# RL6678_IP_SVD register map
Vendor: Realtek
Registers are 32-bit, read-write, reset 0x0 unless marked. A register's access mark holds for its fields unless they carry their own. Offsets are from the block's base; [hi:lo] are bit positions; {n}, {i} and the like mark numbered series.

## AUDIO_REG
Base 0x4100B000
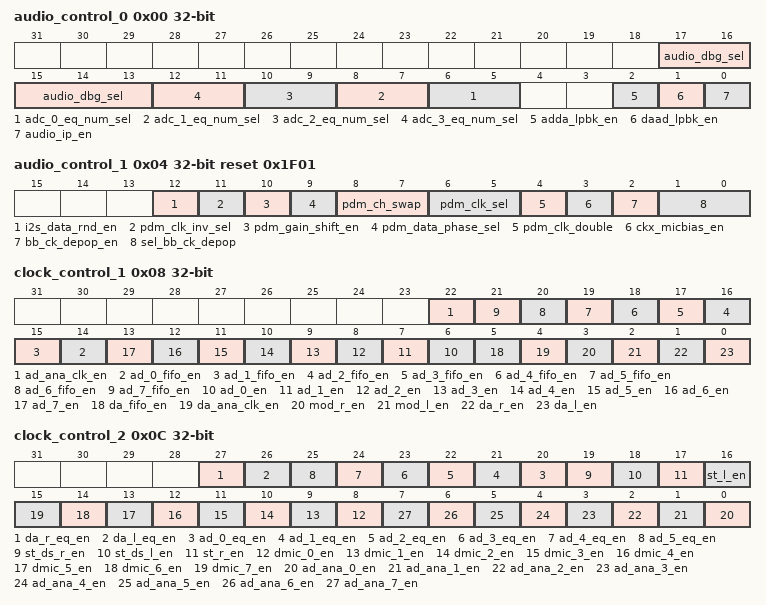
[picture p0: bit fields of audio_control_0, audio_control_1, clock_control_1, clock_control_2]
0x00 audio_control_0 — Audio Control Register 0
  [17:13] audio_dbg_sel — Debug probe selcetion
  [2n+6:2n+5] adc_{n}_eq_num_sel (n=0..3) — 00: 5 band 01: 3 band 02: 0 band 11: Reserved
  [2] adda_lpbk_en — Digital ADC --> DAC loop back control 1'b0: Disable 1'b1: Enable
  [1] daad_lpbk_en — Digital DAC --> ADC loop back control 1'b0: Disable 1'b1: Enable
  [0] audio_ip_en
0x04 audio_control_1 reset 0x1F01 — Audio Control Register 1
  [12] i2s_data_rnd_en
  [11] pdm_clk_inv_sel
  [10] pdm_gain_shift_en
  [9] pdm_data_phase_sel
  [8:7] pdm_ch_swap
  [6:5] pdm_clk_sel — PDM clock selection 2'b0: 5MHz 2'b1: 2.5MHz 2'b2: 6.67MHz
  [4] pdm_clk_double
  [3] ckx_micbias_en
  [2] bb_ck_depop_en
  [1:0] sel_bb_ck_depop
0x08 clock_control_1 — Clock Control Register 1
  [22] ad_ana_clk_en — ADC analog clock enable
  [n+14] ad_{n}_fifo_en (n=0..7) — ADC channel {n} FIFO clock enable
  [n+6] ad_{n}_en (n=0..7) — ADC channel {n} clock enable
  [5] da_fifo_en — DAC FIFO clock enable
  [4] da_ana_clk_en — DAC/ADC analog clock enable
  [3] mod_r_en — SDM R channel clock enable
  [2] mod_l_en — SDM L channel clock enable
  [1] da_r_en — DAC R channel clock enable
  [0] da_l_en — DAC L channel clock enable
0x0C clock_control_2 — Clock Control Register 2
  [27] da_r_eq_en — DAC R channel EQ clock enable
  [26] da_l_eq_en — DAC L channel EQ clock enable
  [n+20] ad_{n}_eq_en (n=0..5) — ADC channel {n} EQ clock enable
  [19] st_ds_r_en — Sidetone downsaple path R channel clock enable
  [18] st_ds_l_en — Sidetone downsaple path L channel clock enable
  [17] st_r_en — Sidetone R channel clock enable
  [16] st_l_en — Sidetone L channel clock enable
  [n+8] dmic_{n}_en (n=0..7) — ADC filter channel {n} clock enable: dmic path
  [n] ad_ana_{n}_en (n=0..7) — ADC filter channel {n} clock enable: analog ADC path
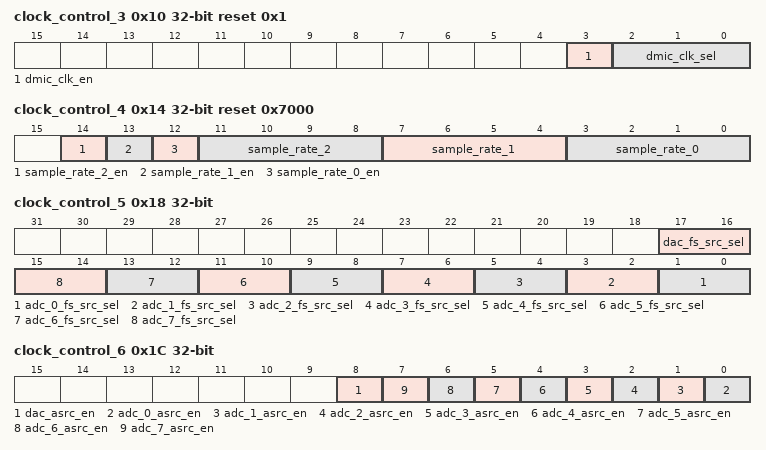
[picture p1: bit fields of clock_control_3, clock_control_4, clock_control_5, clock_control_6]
0x10 clock_control_3 reset 0x1 — Clock Control Register 3
  [3] dmic_clk_en — Digital microphone clock enable
  [2:0] dmic_clk_sel — Set clock of digital microphone 3'b000: 5MHz 3'b001: 2.5MHz 3'b010: 1.25MHz 3'b011: 625kHz 3'b100: 312.5kHz 3'b101: Reserved 3'b110: Reserved 3'b111: 769.2kHz
0x14 clock_control_4 reset 0x7000 — Clock Control Register 4
  [14] sample_rate_2_en — Sample rate source 2 power enable
  [13] sample_rate_1_en — Sample rate source 1 power enable
  [12] sample_rate_0_en — Sample rate source 0 power enable
  [11:8] sample_rate_2 — Set sample rate source 2 4'h0: 48K 4'h1: 96K 4'h2: 192K 4'h3: 32K 4'h4: 176.4K 4'h5: 16K 4'h6: Reserved 4'h7: 8K 4'h8: 44.1K 4'h9: 88.2K 4'ha:24K 4'hb: 12K 4'hc: 22.05K 4'hd: 11.025K 4'he~4'hf: Reserved
  [7:4] sample_rate_1 — Set sample rate source 1 4'h0: 48K 4'h1: 96K 4'h2: 192K 4'h3: 32K 4'h4: 176.4K 4'h5: 16K 4'h6: Reserved 4'h7: 8K 4'h8: 44.1K 4'h9: 88.2K 4'ha:24K 4'hb: 12K 4'hc: 22.05K 4'hd: 11.025K 4'he~4'hf: Reserved
  [3:0] sample_rate_0 — Set sample rate source 0 4'h0: 48K 4'h1: 96K 4'h2: 192K 4'h3: 32K 4'h4: 176.4K 4'h5: 16K 4'h6: Reserved 4'h7: 8K 4'h8: 44.1K 4'h9: 88.2K 4'ha:24K 4'hb: 12K 4'hc: 22.05K 4'hd: 11.025K 4'he~4'hf: Reserved
0x18 clock_control_5 — Clock Control Register 5
  [17:16] dac_fs_src_sel — DAC path sample rate source selection 2'b00: Source 0 2'b01: Source 1 2'b10: Source 2
  [2n+1:2n] adc_{n}_fs_src_sel (n=0..7) — Channel {n} ADC path sample rate source selection 2'b00: Source 0 2'b01: Source 1 2'b10: Source 2
0x1C clock_control_6 — Clock Control Register 6
  [8] dac_asrc_en — DAC path ASRC enable 0: Disable 1: Enable If ASRC is enabled, sample_rate becomes useless.
  [n] adc_{n}_asrc_en (n=0..7) — Channel {n} ADC path ASRC enable 0: Disable 1: Enable If ASRC is enabled, sample_rate becomes useless.
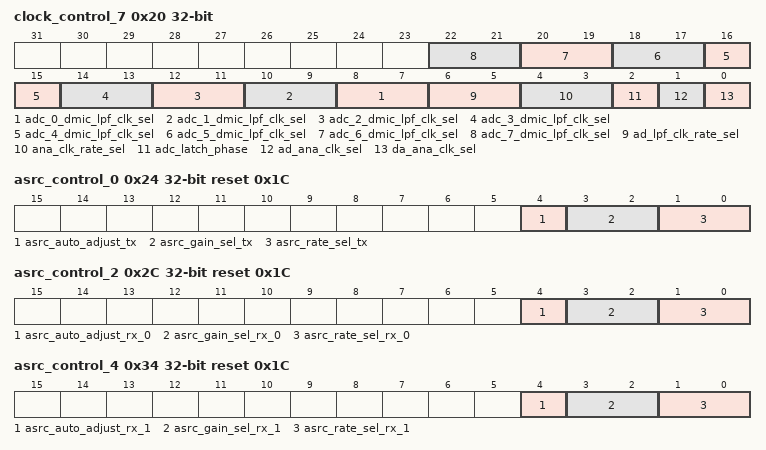
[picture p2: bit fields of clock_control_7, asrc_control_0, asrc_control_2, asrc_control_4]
0x20 clock_control_7 — Clock Control Register 7
  [2n+8:2n+7] adc_{n}_dmic_lpf_clk_sel (n=0..7) — Channel {n} ADC path DMIC LPF clock 2'b00: 10M 2'b01: 5M 2'b10: 2.5M 2'b11: 769.2*2K
  [6:5] ad_lpf_clk_rate_sel — Set AD LPF clock 0: 10MHz 1: 5MHz 2: 2.5MHz 3: Reserved
  [4:3] ana_clk_rate_sel — Set DA/AD analog clock 0: 10MHz 1: 5MHz 2: 2.5MHz 3: Reserved
  [2] adc_latch_phase — Set latch adc data phase 1'b0: Inphase 1'b1: Inverse phase
  [1] ad_ana_clk_sel — Set clk_ad_ana phase 1'b0: Inphase 1'b1: Inverse phase
  [0] da_ana_clk_sel — Set clk_da_ana phase 1'b0: Inphase 1'b1: Inverse phase
0x24 asrc_control_0 reset 0x1C
  [4] asrc_auto_adjust_tx — HW auto adjust convergence rate 0: Disable 1: Enable
  [3:2] asrc_gain_sel_tx — ASRC convergence rate: larger is faster but more noisy
  [1:0] asrc_rate_sel_tx — 0: fs supports 4kHz ~ 60kHz 1: fs supports 60kHz ~ 120kHz 2: fs supports 120kHz ~ 200kHz 3: Reserved
0x28 asrc_control_1 — ASRC Control Register 1
  [23:0] asrc_sdm_inti_tx — Set initial value of tracked frequency
0x2C asrc_control_2 reset 0x1C — ASRC Control Register 2
  [4] asrc_auto_adjust_rx_0 — HW auto adjust convergence rate 0: Disable 1: Enable
  [3:2] asrc_gain_sel_rx_0 — ASRC convergence rate: larger is faster but more noisy
  [1:0] asrc_rate_sel_rx_0 — 0: fs supports 4kHz ~ 60kHz 1: fs supports 60kHz ~ 120kHz 2/3: Reserved
0x30 asrc_control_3 — ASRC Control Register 3
  [23:0] asrc_sdm_inti_rx_0 — Set initial value of tracked frequency
0x34 asrc_control_4 reset 0x1C — ASRC Control Register 4
  [4] asrc_auto_adjust_rx_1 — HW auto adjust convergence rate 0: Disable 1: Enable
  [3:2] asrc_gain_sel_rx_1 — ASRC convergence rate: larger is faster but more noisy
  [1:0] asrc_rate_sel_rx_1 — 0: fs supports 4kHz ~ 60kHz 1: fs supports 60kHz ~ 120kHz 2/3: Reserved
0x38 asrc_control_5 — ASRC Control Register 5
  [23:0] asrc_sdm_inti_rx_1 — Set initial value of tracked frequency
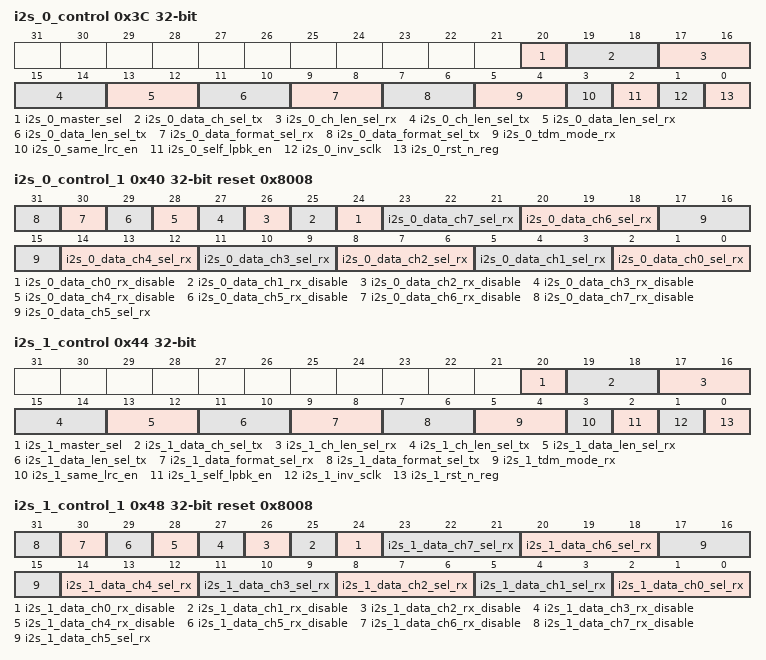
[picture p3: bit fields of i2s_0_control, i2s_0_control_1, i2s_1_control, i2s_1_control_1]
0x3C i2s_0_control
  [20] i2s_0_master_sel — I2S 0 master source selection 1'b0: SPORT internal 1'b1: external I2S
  [19:18] i2s_0_data_ch_sel_tx — I2S 0 Tx channel data channel 2'b00: L/R 2'b01: R/L 2'b10: L/L 2'b11: R/R
  [17:16] i2s_0_ch_len_sel_rx — I2S 0 Rx channel chennel length 2'b00: 16 bits 2'b01: 32 bits 2'b10: 24 bits 2'b11: 8 bits
  [15:14] i2s_0_ch_len_sel_tx — I2S 0 Tx channel channel length 2'b00: 16 bits 2'b01: 32 bits 2'b10: 24 bits 2'b11: 8 bits
  [13:12] i2s_0_data_len_sel_rx — I2S 0 Rx channel data length 2'b00: 16 bits 2'b10: 24 bits 2'b11: 8 bits
  [11:10] i2s_0_data_len_sel_tx — I2S 0 Tx channel data length 2'b00: 16 bits 2'b10: 24 bits 2'b11: 8 bits
  [9:8] i2s_0_data_format_sel_rx — I2S 0 Rx channel data format 2'b00: I2S 2'b01: left-justified 2'b10: PCM mode A 2'b11: PCM mode B
  [7:6] i2s_0_data_format_sel_tx — I2S 0 Tx channel data format 2'b00: I2S 2'b01: left-justified 2'b10: PCM mode A 2'b11: PCM mode B
  [5:4] i2s_0_tdm_mode_rx — I2S 0 Rx channel TDM mode 0: 2 channels 1: 4 channels 2: 6 channels 3: 8 channels
  [3] i2s_0_same_lrc_en — I2S 0 1'b1: LRC_TX share to LRC_RX
  [2] i2s_0_self_lpbk_en — I2S 0 1'b1: internal loopback mode is enabled
  [1] i2s_0_inv_sclk — I2S 0 1'b1: I2S/PCM bit clock is inverted
  [0] i2s_0_rst_n_reg — I2S 0 1'b1: rst_n to audio digital IP is de-asserted 1'b0: rst_n to audio digital IP is asserted
0x40 i2s_0_control_1 reset 0x8008 — I2S 0 Control Register 1
  [n+24] i2s_0_data_ch{n}_rx_disable (n=0..7) — I2S 0 Rx channel data channel {n} 1: Disable 0: Enable
  [3n+2:3n] i2s_0_data_ch{n}_sel_rx (n=0..7) — I2S 0 Rx channel data channel {n} 0: CH0 1: CH1 2: CH2 3: CH3 4: CH4 5: CH5 6: CH6 7: CH7
0x44 i2s_1_control
  [20] i2s_1_master_sel — I2S 1 master source selection 1'b0: SPORT internal 1'b1: external I2S
  [19:18] i2s_1_data_ch_sel_tx — I2S 1 Tx channel data channel 2'b00: L/R 2'b01: R/L 2'b10: L/L 2'b11: R/R
  [17:16] i2s_1_ch_len_sel_rx — I2S 1 Rx channel chennel length 2'b00: 16 bits 2'b01: 32 bits 2'b10: 24 bits 2'b11: 8 bits
  [15:14] i2s_1_ch_len_sel_tx — I2S 1 Tx channel channel length 2'b00: 16 bits 2'b01: 32 bits 2'b10: 24 bits 2'b11: 8 bits
  [13:12] i2s_1_data_len_sel_rx — I2S 1 Rx channel data length 2'b00: 16 bits 2'b10: 24 bits 2'b11: 8 bits
  [11:10] i2s_1_data_len_sel_tx — I2S 1 Tx channel data length 2'b00: 16 bits 2'b10: 24 bits 2'b11: 8 bits
  [9:8] i2s_1_data_format_sel_rx — I2S 1 Rx channel data format 2'b00: I2S 2'b01: left-justified 2'b10: PCM mode A 2'b11: PCM mode B
  [7:6] i2s_1_data_format_sel_tx — I2S 1 Tx channel data format 2'b00: I2S 2'b01: left-justified 2'b10: PCM mode A 2'b11: PCM mode B
  [5:4] i2s_1_tdm_mode_rx — I2S 1 Rx channel TDM mode 0: 2 channels 1: 4 channels 2: 6 channels 3: 8 channels
  [3] i2s_1_same_lrc_en — I2S 1 1'b1: LRC_TX share to LRC_RX
  [2] i2s_1_self_lpbk_en — I2S 1 1'b1: internal loopback mode is enabled
  [1] i2s_1_inv_sclk — I2S 1 1'b1: I2S/PCM bit clock is inverted
  [0] i2s_1_rst_n_reg — I2S 1 1'b1: rst_n to audio digital IP is de-asserted 1'b0: rst_n to audio digital IP is asserted
0x48 i2s_1_control_1 reset 0x8008 — I2S 1 Control Register 1
  [n+24] i2s_1_data_ch{n}_rx_disable (n=0..7) — I2S 1 Rx channel data channel {n} 1: Disable 0: Enable
  [3n+2:3n] i2s_1_data_ch{n}_sel_rx (n=0..7) — I2S 1 Rx channel data channel {n} 0: CH0 1: CH1 2: CH2 3: CH3 4: CH4 5: CH5 6: CH6 7: CH7
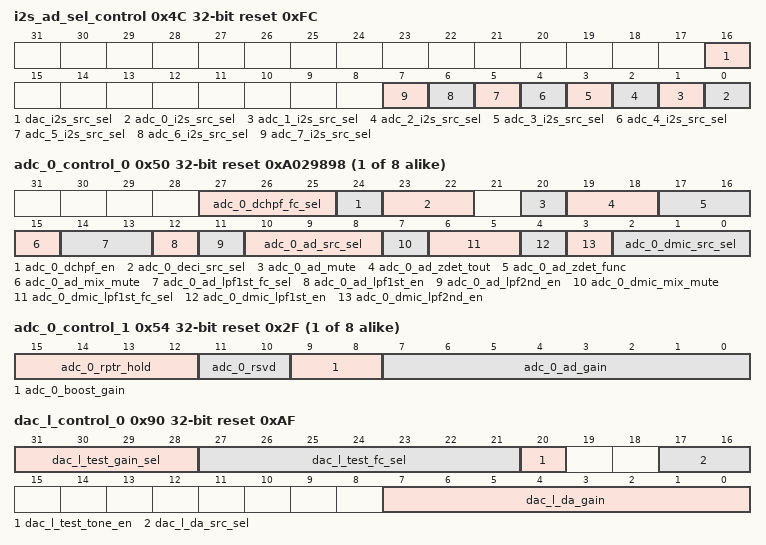
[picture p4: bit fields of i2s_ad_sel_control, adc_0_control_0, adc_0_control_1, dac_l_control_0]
0x4C i2s_ad_sel_control reset 0xFC — I2S ADC Selection Control Register
  [16] dac_i2s_src_sel — DAC path I2S selection 1: I2S 1 0: I2S 0
  [n] adc_{n}_i2s_src_sel (n=0..7) — Channel {n} ADC path I2S selection 1: I2S 1 0: I2S 0
{0x50+8i} adc_{i}_control_0 reset 0xA029898 (i=0..7) — ADC Channel {i} Control Register 0
  [27:25] adc_{i}_dchpf_fc_sel — Channel {i} ADC path high pass filter Fc (Fc: -3dB) 0: 5e10^-3 Fs 1: 2.5e10^-3 Fs 2: 1.125e10^-3 Fs 3: 6.25e10^-4 Fs 4: 3.125e10^-4 Fs 5: 1.5625e10^-4 Fs 6: 7.8125e10^-5 Fs 7: 3.90625e10^-5 Fs
  [24] adc_{i}_dchpf_en — Channel {i} ADC path high pass filter enable control (filter DC) 0: Disable 1: Enable
  [23:22] adc_{i}_deci_src_sel — Channel {i} ADC path decimation source select 0: ADC 1: ANC 2: MUSIC 3: ANC + MUSIC
  [20] adc_{i}_ad_mute — Channel {i} ADC path mute 0: Un-Mute 1: Mute
  [19:18] adc_{i}_ad_zdet_tout — Channel {i} ADC path zero detection time out select 2'b00: 1024*16 samples 2'b01: 1024*32 samples 2'b10: 1024*64 samples 2'b11: 64 samples
  [17:16] adc_{i}_ad_zdet_func — Channel {i} ADC path zero detection function select 2'b00: immediate change 2'b01: zero detection & immediate change 2'b10: zdet & step 2'b11: zdet & timeout step
  [15] adc_{i}_ad_mix_mute — Channel {i} ADC input path mute 0: Unmute 1: Mute
  [14:13] adc_{i}_ad_lpf1st_fc_sel — Channel {i} ADC path SRC 1st LPF FC
  [12] adc_{i}_ad_lpf1st_en — Channel {i} ADC path SRC 1st LPF control 0: Disable 1: Enable
  [11] adc_{i}_ad_lpf2nd_en — Channel {i} ADC path SRC 2nd LPF control 0: Disable 1: Enable
  [10:8] adc_{i}_ad_src_sel — Channel {i} ANA ADC source selection 3'd0: ADC 1 3'd1: ADC 2 3'd2: ADC 3 3'd3: ADC 4 3'd4: ADC 5
  [7] adc_{i}_dmic_mix_mute — Channel {i} DMIC input path mute 0: Unmute 1: Mute
  [6:5] adc_{i}_dmic_lpf1st_fc_sel — Channel {i} DMIC path SRC 1st LPF FC
  [4] adc_{i}_dmic_lpf1st_en — Channel {i} DMIC path SRC 1st LPF control 0: Disable 1: Enable
  [3] adc_{i}_dmic_lpf2nd_en — Channel {i} DMIC path SRC 2nd LPF control 0: Disable 1: Enable
  [2:0] adc_{i}_dmic_src_sel — Channel {i} DMIC source selection 3'b000: MIC 1 rising 3'b001: MIC 1 falling 3'b010: MIC 2 rising 3'b011: MIC 2 falling 3'b100: MIC 3 rising 3'b101: MIC 3 falling 3'b110: MIC 4 rising 3'b111: MIC 4 falling
{0x54+8i} adc_{i}_control_1 reset 0x2F (i=0..7) — ADC Channel {i} Control Register 1
  [15:12] adc_{i}_rptr_hold — Channel {i} I2S read point hold number rptr_hold = (I2S_fs/ad_fs) - 1
  [11:10] adc_{i}_rsvd — Dummy
  [9:8] adc_{i}_boost_gain — Channel {i} ADC path boost gain control 00: 0dB 01: 12dB 10: 24dB 11: 36dB
  [7:0] adc_{i}_ad_gain — Channel {i} ADC digital volume -17.625dB ~ 48dB in 0.375dB step 8'h00: -17.625dB ... 8'h2f: 0dB 8'h30: 0.375dB ... 8'haf: 48dB
0x90 dac_l_control_0 reset 0xAF — DAC Left Channel Control Register 0
  [31:28] dac_l_test_gain_sel — Channel L DAC path test tone gain control 0 -6.02*(gain_sel)dB
  [27:21] dac_l_test_fc_sel — Channel L DAC path test tone frquency: (fs/192)*(tone_fc_sel+1)Hz
  [20] dac_l_test_tone_en — Channel L DAC path test tone enable
  [17:16] dac_l_da_src_sel — Channel L DAC path input select 0: I2S L channel 1: I2S R channel 2: I2S L+R channel 3: Test tone
  [7:0] dac_l_da_gain — Channel L DAC path dvol gain control (0.375dB/step) 8'hAF: 0dB 8'h00: -65.625dB
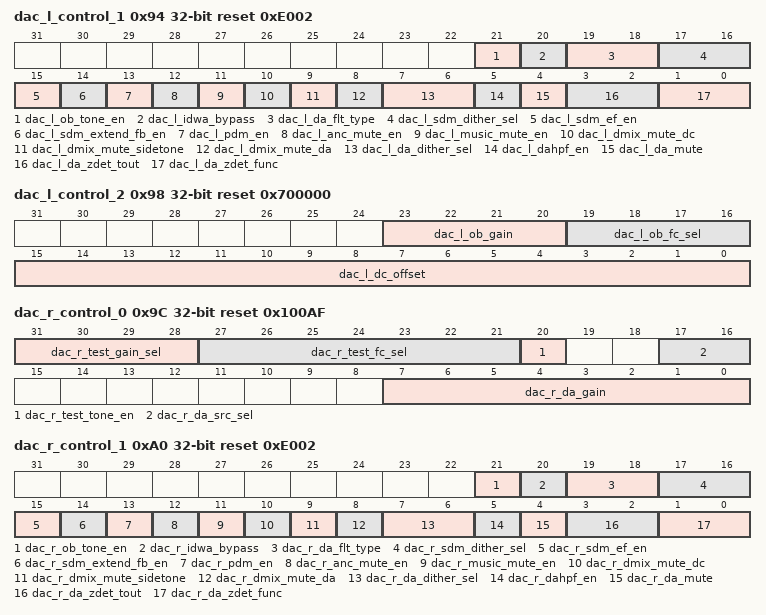
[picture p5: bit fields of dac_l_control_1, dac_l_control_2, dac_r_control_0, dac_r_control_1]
0x94 dac_l_control_1 reset 0xE002 — DAC Left Channel Control Register 1
  [21] dac_l_ob_tone_en — Channel L DAC path Out Band tone enable 0: Disable 1: Enable
  [20] dac_l_idwa_bypass — Channel L DAC path IDWA BYPASS mode 0: Disable 1: Enable (debug purpose)
  [19:18] dac_l_da_flt_type — Channel L DAC path interpolation filter type
  [17:16] dac_l_sdm_dither_sel — Channel L DAC path SDM dither select 2'b00: Disable 2'b01: LSB 2'b10: LSB+1 2'b11: LSB+2
  [15] dac_l_sdm_ef_en — Channel L DAC path 2nd order SDM enable 0: Disable 1: Enable
  [14] dac_l_sdm_extend_fb_en — Channel L DAC path feedback extend (for debug purpose; default need turn on) 0: Disable 1: Enable
  [13] dac_l_pdm_en — Channel L DAC path PDM 0: Disable 1: Enable
  [12] dac_l_anc_mute_en — Channel L DAC path ANC output mute enable 1'b0: Unmute 1'b1: Mute
  [11] dac_l_music_mute_en — Channel L DAC path music output mute enable 1'b0: Unmute 1'b1: Mute
  [10] dac_l_dmix_mute_dc — Channel L DAC path 128fs-domain mixer a DC from dac_l_tone_compensation_offset 1'b0: Unmute 1'b1: Mute
  [9] dac_l_dmix_mute_sidetone — Channel L DAC path 128fs-domain mixer sidetone path mute enable 1'b0: Unmute 1'b1: Mute
  [8] dac_l_dmix_mute_da — Channel L DAC path 128fs-domain mixer da path mute enable 1'b0: Unmute 1'b1: Mute
  [7:6] dac_l_da_dither_sel — Channel L DAC path dither select 2'b00: Disable 2'b01: LSB 2'b10: LSB+1 2'b11: LSB+2
  [5] dac_l_dahpf_en — Channel L DAC path Narrow-band 1st HPF enable control 0: Disable 1: Enable
  [4] dac_l_da_mute — Channel L DAC path dvol mute enable 1'b0: Unmute 1'b1: Mute
  [3:2] dac_l_da_zdet_tout — Channel L DAC path zero detection time out select 2'b00: 1024*16 samples 2'b01: 1024*32 samples 2'b10: 1024*64 samples 2'b11: 64 samples
  [1:0] dac_l_da_zdet_func — Channel L DAC path zero detection function select 2'b00: immediate change 2'b01: zero detection & immediate change 2'b10: zero detection & step 2'b11: zero detection & timeout step
0x98 dac_l_control_2 reset 0x700000 — DAC Left Channel Control Register 2
  [23:20] dac_l_ob_gain — Channel L DAC path out Band tone gain -20dB - (6 * dac_l_ob_gain )
  [19:16] dac_l_ob_fc_sel — Channel L DAC path out Band tone frequency 100kHz * (dac_l_ob_fc_sel+1)
  [15:0] dac_l_dc_offset — Channel L DAC path 128fs-domain mixe a DC compensation for spur issue 2's complemet
0x9C dac_r_control_0 reset 0x100AF — DAC Right Channel Control Register 0
  [31:28] dac_r_test_gain_sel — Channel R DAC path test tone gain control 0 -6.02*(gain_sel)dB
  [27:21] dac_r_test_fc_sel — Channel R DAC path test tone frquency: (fs/192)*(tone_fc_sel+1)Hz
  [20] dac_r_test_tone_en — Channel R DAC path test tone enable
  [17:16] dac_r_da_src_sel — Channel R DAC path input select 0: I2S L channel 1: I2S R channel 2: I2S L+R channel 3: Test tone
  [7:0] dac_r_da_gain — Channel R DAC path dvol gain control (0.375dB/step) 8'hAF: 0dB 8'h00: -65.625dB
0xA0 dac_r_control_1 reset 0xE002 — DAC Right Channel Control Register 1
  [21] dac_r_ob_tone_en — Channel R DAC path Out Band tone enable 0: Disable 1: Enable
  [20] dac_r_idwa_bypass — Channel R DAC path IDWA BYPASS mode 0: Disable 1: Enable (debug purpose)
  [19:18] dac_r_da_flt_type — Channel R DAC path interpolation filter type
  [17:16] dac_r_sdm_dither_sel — Channel R DAC path SDM dither select 2'b00: Disable 2'b01: LSB 2'b10: LSB+1 2'b11: LSB+2
  [15] dac_r_sdm_ef_en — Channel R DAC path 2nd order SDM enable 0: Disable 1: Enable
  [14] dac_r_sdm_extend_fb_en — Channel R DAC path feedback extend (for debug purpose; default need turn on) 0: Disable 1: Enable
  [13] dac_r_pdm_en — Channel R DAC path PDM 0: Disable 1: Enable
  [12] dac_r_anc_mute_en — Channel R DAC path ANC output mute enable 1'b0: Unmute 1'b1: Mute
  [11] dac_r_music_mute_en — Channel R DAC path music output mute enable 1'b0: Unmute 1'b1: Mute
  [10] dac_r_dmix_mute_dc — Channel R DAC path 128fs-domain mixer a DC from dac_r_tone_compensation_offset 1'b0: Unmute 1'b1: Mute
  [9] dac_r_dmix_mute_sidetone — Channel R DAC path 128fs-domain mixer sidetone path mute enable 1'b0: Unmute 1'b1: Mute
  [8] dac_r_dmix_mute_da — Channel R DAC path 128fs-domain mixer da path mute enable 1'b0: Unmute 1'b1: Mute
  [7:6] dac_r_da_dither_sel — Channel R DAC path dither select 2'b00: Disable 2'b01: LSB 2'b10: LSB+1 2'b11: LSB+2
  [5] dac_r_dahpf_en — Channel R DAC path Narrow-band 1st HPF enable control 0: Disable 1: Enable
  [4] dac_r_da_mute — Channel R DAC path dvol mute enable 1'b0: Unmute 1'b1: Mute
  [3:2] dac_r_da_zdet_tout — Channel R DAC path zero detection time out select 2'b00: 1024*16 samples 2'b01: 1024*32 samples 2'b10: 1024*64 samples 2'b11: 64 samples
  [1:0] dac_r_da_zdet_func — Channel R DAC path zero detection function select 2'b00: immediate change 2'b01: zero detection & immediate change 2'b10: zero detection & step 2'b11: zero detection & timeout step
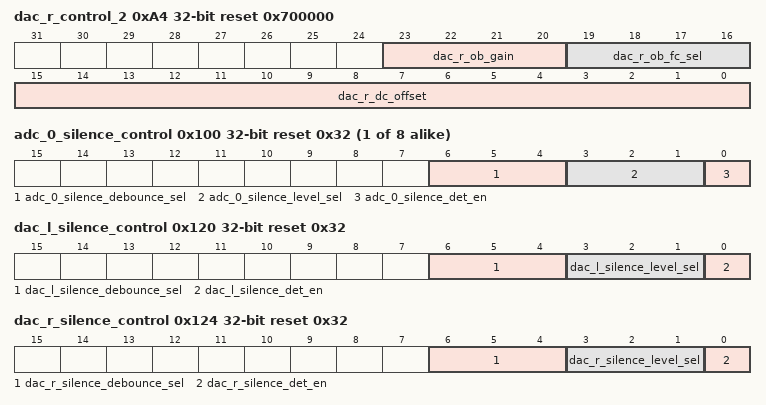
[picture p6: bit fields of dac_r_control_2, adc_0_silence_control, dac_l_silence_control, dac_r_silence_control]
0xA4 dac_r_control_2 reset 0x700000 — DAC Right Channel Control Register 2
  [23:20] dac_r_ob_gain — Channel R DAC path out Band tone gain -20dB - (6 * dac_l_ob_gain )
  [19:16] dac_r_ob_fc_sel — Channel R DAC path out Band tone frequency 100kHz * (dac_l_ob_fc_sel+1)
  [15:0] dac_r_dc_offset — Channel R DAC path 128fs-domain mixe a DC compensation for spur issue 2's complemet
{0x100+4i} adc_{i}_silence_control reset 0x32 (i=0..7) — ADC Channel {i} Silence Control Register
  [6:4] adc_{i}_silence_debounce_sel — Channel {i} ADC path silence detection debounce (48K) 3'b000: 80ms 3'b001: 160ms 3'b010: 320ms 3'b011: 640ms 3'b100: 1.28s 3'b101: 2.56s 3'b110: 5.12s 3'b111: 0.16ms
  [3:1] adc_{i}_silence_level_sel — Channel {i} ADC path silence detection threshold 3'b000: -54db 3'b001: -60db 3'b010: -66db 3'b011: -72db 3'b100: -78db 3'b101: -84db 3'b110: -90db 3'b111: -96db
  [0] adc_{i}_silence_det_en — Channel {i} ADC path silence detection enable 0: Disable 1: Enable
0x120 dac_l_silence_control reset 0x32 — DAC Left Channel Silence Control Register
  [6:4] dac_l_silence_debounce_sel — Channel L DAC path silence detection debounce (48K) 3'b000: 80ms 3'b001: 160ms 3'b010: 320ms 3'b011: 640ms 3'b100: 1.28s 3'b101: 2.56s 3'b110: 5.12s 3'b111: 0.16ms
  [3:1] dac_l_silence_level_sel — Channel L DAC path silence detection threshold 3'b000: -78db 3'b001: -84db 3'b010: -90db 3'b011: -102db 3'b100: -108db 3'b101: -114db 3'b110: -126db 3'b111: -132db
  [0] dac_l_silence_det_en — Channel L DAC path silence detection enable 0: Disable 1: Enable
0x124 dac_r_silence_control reset 0x32 — DAC Right Channel Silence Control Register
  [6:4] dac_r_silence_debounce_sel — Channel R DAC path silence detection debounce (48K) 3'b000: 80ms 3'b001: 160ms 3'b010: 320ms 3'b011: 640ms 3'b100: 1.28s 3'b101: 2.56s 3'b110: 5.12s 3'b111: 0.16ms
  [3:1] dac_r_silence_level_sel — Channel R DAC path silence detection threshold 3'b000: -78db 3'b001: -84db 3'b010: -90db 3'b011: -102db 3'b100: -108db 3'b101: -114db 3'b110: -126db 3'b111: -132db
  [0] dac_r_silence_det_en — Channel R DAC path silence detection enable 0: Disable 1: Enable
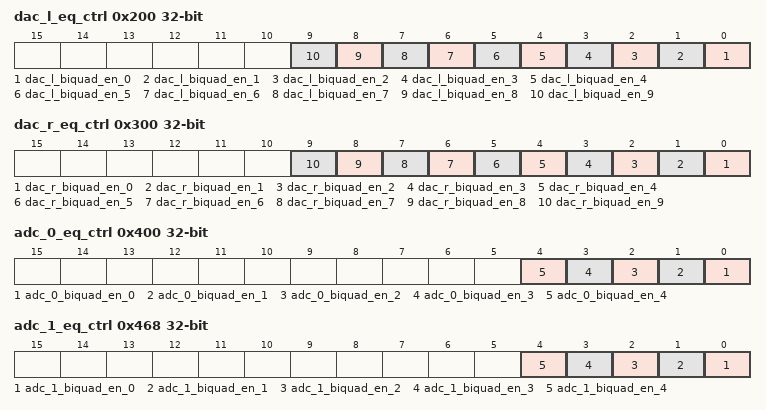
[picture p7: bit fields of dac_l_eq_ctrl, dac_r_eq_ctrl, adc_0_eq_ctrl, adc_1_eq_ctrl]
0x200 dac_l_eq_ctrl — DAC Left Channel EQ Control Register
  [n] dac_l_biquad_en_{n} (n=0..9) — DAC Lch EQ {n}-band biquad enable 0: Disable 1: Enable
{0x204+0x14*i} dac_l_biquad_h0_{i} reset 0x2000000 (i=0..9) — DAC Left Channel EQ Band {i} Biquad H0 Register
  [28:0] dac_l_biquad_h0_{i} — DAC Lch EQ {i}-band coef. h0 2's complement in 4.25 format, i. e. the range is from -8~7.99.
{0x208+0x14*i} dac_l_biquad_b1_{i} (i=0..9) — DAC Left Channel EQ Band {i} Biquad B1 Register
  [28:0] dac_l_biquad_b1_{i} — DAC Lch EQ {i}-band coef. b1 2's complement in 4.25 format, i. e. the range is from -8~7.99.
{0x20C+0x14*i} dac_l_biquad_b2_{i} (i=0..9) — DAC Left Channel EQ Band {i} Biquad B2 Register
  [28:0] dac_l_biquad_b2_{i} — DAC Lch EQ {i}-band coef. b2 2's complement in 4.25 format, i. e. the range is from -8~7.99.
{0x210+0x14*i} dac_l_biquad_a1_{i} (i=0..9) — DAC Left Channel EQ Band {i} Biquad A1 Register
  [28:0] dac_l_biquad_a1_{i} — DAC Lch EQ {i}-band coef. a1 2's complement in 4.25 format, i. e. the range is from -8~7.99.
{0x214+0x14*i} dac_l_biquad_a2_{i} (i=0..9) — DAC Left Channel EQ Band {i} Biquad A2 Register
  [28:0] dac_l_biquad_a2_{i} — DAC Lch EQ {i}-band coef. a2 2's complement in 4.25 format, i. e. the range is from -8~7.99.
0x300 dac_r_eq_ctrl — DAC Right Channel EQ Control Register
  [n] dac_r_biquad_en_{n} (n=0..9) — DAC Rch EQ {n}-band biquad enable 0: Disable 1: Enable
{0x304+0x14*i} dac_r_biquad_h0_{i} reset 0x2000000 (i=0..9) — DAC Right Channel EQ Band {i} Biquad H0 Register
  [28:0] dac_r_biquad_h0_{i} — DAC Rch EQ {i}-band coef. h0 2's complement in 4.25 format, i. e. the range is from -8~7.99.
{0x308+0x14*i} dac_r_biquad_b1_{i} (i=0..9) — DAC Right Channel EQ Band {i} Biquad B1 Register
  [28:0] dac_r_biquad_b1_{i} — DAC Rch EQ {i}-band coef. b1 2's complement in 4.25 format, i. e. the range is from -8~7.99.
{0x30C+0x14*i} dac_r_biquad_b2_{i} (i=0..9) — DAC Right Channel EQ Band {i} Biquad B2 Register
  [28:0] dac_r_biquad_b2_{i} — DAC Rch EQ {i}-band coef. b2 2's complement in 4.25 format, i. e. the range is from -8~7.99.
{0x310+0x14*i} dac_r_biquad_a1_{i} (i=0..9) — DAC Right Channel EQ Band {i} Biquad A1 Register
  [28:0] dac_r_biquad_a1_{i} — DAC Rch EQ {i}-band coef. a1 2's complement in 4.25 format, i. e. the range is from -8~7.99.
{0x314+0x14*i} dac_r_biquad_a2_{i} (i=0..9) — DAC Right Channel EQ Band {i} Biquad A2 Register
  [28:0] dac_r_biquad_a2_{i} — DAC Rch EQ {i}-band coef. a2 2's complement in 4.25 format, i. e. the range is from -8~7.99.
0x400 adc_0_eq_ctrl — ADC Channel 0 EQ Control Register
  [n] adc_0_biquad_en_{n} (n=0..4) — ADC channel 0 EQ {n}-band biquad enable 0: Disable 1: Enable
{0x404+0x14*i} adc_0_biquad_h0_{i} reset 0x2000000 (i=0..4) — ADC Channel 0 EQ Band {i} Biquad H0 Register
  [28:0] adc_0_biquad_h0_{i} — ADC channel 0 EQ {i}-band coef. h0 2's complement in 4.25 format, i. e. the range is from -8~7.99.
{0x408+0x14*i} adc_0_biquad_b1_{i} (i=0..4) — ADC Channel 0 EQ Band {i} Biquad B1 Register
  [28:0] adc_0_biquad_b1_{i} — ADC channel 0 EQ {i}-band coef. b1 2's complement in 4.25 format, i. e. the range is from -8~7.99.
{0x40C+0x14*i} adc_0_biquad_b2_{i} (i=0..4) — ADC Channel 0 EQ Band {i} Biquad B2 Register
  [28:0] adc_0_biquad_b2_{i} — ADC channel 0 EQ {i}-band coef. b2 2's complement in 4.25 format, i. e. the range is from -8~7.99.
{0x410+0x14*i} adc_0_biquad_a1_{i} (i=0..4) — ADC Channel 0 EQ Band {i} Biquad A1 Register
  [28:0] adc_0_biquad_a1_{i} — ADC channel 0 EQ {i}-band coef. a1 2's complement in 4.25 format, i. e. the range is from -8~7.99.
{0x414+0x14*i} adc_0_biquad_a2_{i} (i=0..4) — ADC Channel 0 EQ Band {i} Biquad A2 Register
  [28:0] adc_0_biquad_a2_{i} — ADC channel 0 EQ {i}-band coef. a2 2's complement in 4.25 format, i. e. the range is from -8~7.99.
0x468 adc_1_eq_ctrl — ADC Channel 1 EQ Control Register
  [n] adc_1_biquad_en_{n} (n=0..4) — ADC channel 1 EQ {n}-band biquad enable 0: Disable 1: Enable
{0x46C+0x14*i} adc_1_biquad_h0_{i} reset 0x2000000 (i=0..4) — ADC Channel 1 EQ Band {i} Biquad H0 Register
  [28:0] adc_1_biquad_h0_{i} — ADC channel 1 EQ {i}-band coef. h0 2's complement in 4.25 format, i. e. the range is from -8~7.99.
{0x470+0x14*i} adc_1_biquad_b1_{i} (i=0..4) — ADC Channel 1 EQ Band {i} Biquad B1 Register
  [28:0] adc_1_biquad_b1_{i} — ADC channel 1 EQ {i}-band coef. b1 2's complement in 4.25 format, i. e. the range is from -8~7.99.
{0x474+0x14*i} adc_1_biquad_b2_{i} (i=0..4) — ADC Channel 1 EQ Band {i} Biquad B2 Register
  [28:0] adc_1_biquad_b2_{i} — ADC channel 1 EQ {i}-band coef. b2 2's complement in 4.25 format, i. e. the range is from -8~7.99.
{0x478+0x14*i} adc_1_biquad_a1_{i} (i=0..4) — ADC Channel 1 EQ Band {i} Biquad A1 Register
  [28:0] adc_1_biquad_a1_{i} — ADC channel 1 EQ {i}-band coef. a1 2's complement in 4.25 format, i. e. the range is from -8~7.99.
{0x47C+0x14*i} adc_1_biquad_a2_{i} (i=0..4) — ADC Channel 1 EQ Band {i} Biquad A2 Register
  [28:0] adc_1_biquad_a2_{i} — ADC channel 1 EQ {i}-band coef. a2 2's complement in 4.25 format, i. e. the range is from -8~7.99.
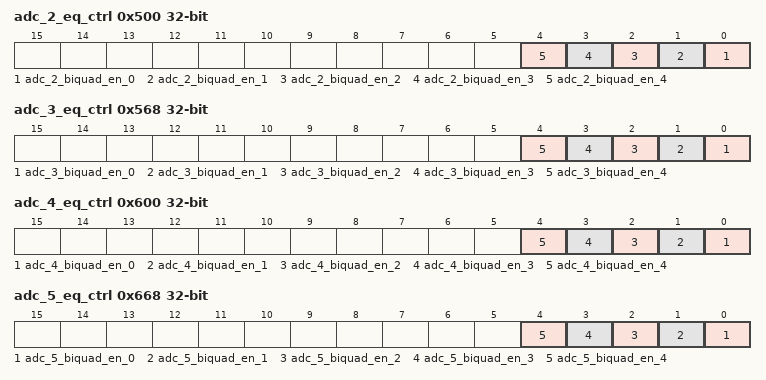
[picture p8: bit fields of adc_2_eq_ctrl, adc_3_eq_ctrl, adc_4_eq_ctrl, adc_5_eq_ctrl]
0x500 adc_2_eq_ctrl — ADC Channel 2 EQ Control Register
  [n] adc_2_biquad_en_{n} (n=0..4) — ADC channel 2 EQ {n}-band biquad enable 0: Disable 1: Enable
{0x504+0x14*i} adc_2_biquad_h0_{i} reset 0x2000000 (i=0..4) — ADC Channel 2 EQ Band {i} Biquad H0 Register
  [28:0] adc_2_biquad_h0_{i} — ADC channel 2 EQ {i}-band coef. h0 2's complement in 4.25 format, i. e. the range is from -8~7.99.
{0x508+0x14*i} adc_2_biquad_b1_{i} (i=0..4) — ADC Channel 2 EQ Band {i} Biquad B1 Register
  [28:0] adc_2_biquad_b1_{i} — ADC channel 2 EQ {i}-band coef. b1 2's complement in 4.25 format, i. e. the range is from -8~7.99.
{0x50C+0x14*i} adc_2_biquad_b2_{i} (i=0..4) — ADC Channel 2 EQ Band {i} Biquad B2 Register
  [28:0] adc_2_biquad_b2_{i} — ADC channel 2 EQ {i}-band coef. b2 2's complement in 4.25 format, i. e. the range is from -8~7.99.
{0x510+0x14*i} adc_2_biquad_a1_{i} (i=0..4) — ADC Channel 2 EQ Band {i} Biquad A1 Register
  [28:0] adc_2_biquad_a1_{i} — ADC channel 2 EQ {i}-band coef. a1 2's complement in 4.25 format, i. e. the range is from -8~7.99.
{0x514+0x14*i} adc_2_biquad_a2_{i} (i=0..4) — ADC Channel 2 EQ Band {i} Biquad A2 Register
  [28:0] adc_2_biquad_a2_{i} — ADC channel 2 EQ {i}-band coef. a2 2's complement in 4.25 format, i. e. the range is from -8~7.99.
0x568 adc_3_eq_ctrl — ADC Channel 3 EQ Control Register
  [n] adc_3_biquad_en_{n} (n=0..4) — ADC channel 3 EQ {n}-band biquad enable 0: Disable 1: Enable
{0x56C+0x14*i} adc_3_biquad_h0_{i} reset 0x2000000 (i=0..4) — ADC Channel 3 EQ Band {i} Biquad H0 Register
  [28:0] adc_3_biquad_h0_{i} — ADC channel 3 EQ {i}-band coef. h0 2's complement in 4.25 format, i. e. the range is from -8~7.99.
{0x570+0x14*i} adc_3_biquad_b1_{i} (i=0..4) — ADC Channel 3 EQ Band {i} Biquad B1 Register
  [28:0] adc_3_biquad_b1_{i} — ADC channel 3 EQ {i}-band coef. b1 2's complement in 4.25 format, i. e. the range is from -8~7.99.
{0x574+0x14*i} adc_3_biquad_b2_{i} (i=0..4) — ADC Channel 3 EQ Band {i} Biquad B2 Register
  [28:0] adc_3_biquad_b2_{i} — ADC channel 3 EQ {i}-band coef. b2 2's complement in 4.25 format, i. e. the range is from -8~7.99.
{0x578+0x14*i} adc_3_biquad_a1_{i} (i=0..4) — ADC Channel 3 EQ Band {i} Biquad A1 Register
  [28:0] adc_3_biquad_a1_{i} — ADC channel 3 EQ {i}-band coef. a1 2's complement in 4.25 format, i. e. the range is from -8~7.99.
{0x57C+0x14*i} adc_3_biquad_a2_{i} (i=0..4) — ADC Channel 3 EQ Band {i} Biquad A2 Register
  [28:0] adc_3_biquad_a2_{i} — ADC channel 3 EQ {i}-band coef. a2 2's complement in 4.25 format, i. e. the range is from -8~7.99.
0x600 adc_4_eq_ctrl — ADC Channel 4 EQ Control Register
  [n] adc_4_biquad_en_{n} (n=0..4) — ADC channel 4 EQ {n}-band biquad enable 0: Disable 1: Enable
{0x604+0x14*i} adc_4_biquad_h0_{i} reset 0x2000000 (i=0..4) — ADC Channel 4 EQ Band {i} Biquad H0 Register
  [28:0] adc_4_biquad_h0_{i} — ADC channel 4 EQ {i}-band coef. h0 2's complement in 4.25 format, i. e. the range is from -8~7.99.
{0x608+0x14*i} adc_4_biquad_b1_{i} (i=0..4) — ADC Channel 4 EQ Band {i} Biquad B1 Register
  [28:0] adc_4_biquad_b1_{i} — ADC channel 4 EQ {i}-band coef. b1 2's complement in 4.25 format, i. e. the range is from -8~7.99.
{0x60C+0x14*i} adc_4_biquad_b2_{i} (i=0..4) — ADC Channel 4 EQ Band {i} Biquad B2 Register
  [28:0] adc_4_biquad_b2_{i} — ADC channel 4 EQ {i}-band coef. b2 2's complement in 4.25 format, i. e. the range is from -8~7.99.
{0x610+0x14*i} adc_4_biquad_a1_{i} (i=0..4) — ADC Channel 4 EQ Band {i} Biquad A1 Register
  [28:0] adc_4_biquad_a1_{i} — ADC channel 4 EQ {i}-band coef. a1 2's complement in 4.25 format, i. e. the range is from -8~7.99.
{0x614+0x14*i} adc_4_biquad_a2_{i} (i=0..4) — ADC Channel 4 EQ Band {i} Biquad A2 Register
  [28:0] adc_4_biquad_a2_{i} — ADC channel 4 EQ {i}-band coef. a2 2's complement in 4.25 format, i. e. the range is from -8~7.99.
0x668 adc_5_eq_ctrl — ADC Channel 5 EQ Control Register
  [n] adc_5_biquad_en_{n} (n=0..4) — ADC channel 5 EQ {n}-band biquad enable 0: Disable 1: Enable
{0x66C+0x14*i} adc_5_biquad_h0_{i} reset 0x2000000 (i=0..4) — ADC Channel 5 EQ Band {i} Biquad H0 Register
  [28:0] adc_5_biquad_h0_{i} — ADC channel 5 EQ {i}-band coef. h0 2's complement in 4.25 format, i. e. the range is from -8~7.99.
{0x670+0x14*i} adc_5_biquad_b1_{i} (i=0..4) — ADC Channel 5 EQ Band {i} Biquad B1 Register
  [28:0] adc_5_biquad_b1_{i} — ADC channel 5 EQ {i}-band coef. b1 2's complement in 4.25 format, i. e. the range is from -8~7.99.
{0x674+0x14*i} adc_5_biquad_b2_{i} (i=0..4) — ADC Channel 5 EQ Band {i} Biquad B2 Register
  [28:0] adc_5_biquad_b2_{i} — ADC channel 5 EQ {i}-band coef. b2 2's complement in 4.25 format, i. e. the range is from -8~7.99.
{0x678+0x14*i} adc_5_biquad_a1_{i} (i=0..4) — ADC Channel 5 EQ Band {i} Biquad A1 Register
  [28:0] adc_5_biquad_a1_{i} — ADC channel 5 EQ {i}-band coef. a1 2's complement in 4.25 format, i. e. the range is from -8~7.99.
{0x67C+0x14*i} adc_5_biquad_a2_{i} (i=0..4) — ADC Channel 5 EQ Band {i} Biquad A2 Register
  [28:0] adc_5_biquad_a2_{i} — ADC channel 5 EQ {i}-band coef. a2 2's complement in 4.25 format, i. e. the range is from -8~7.99.
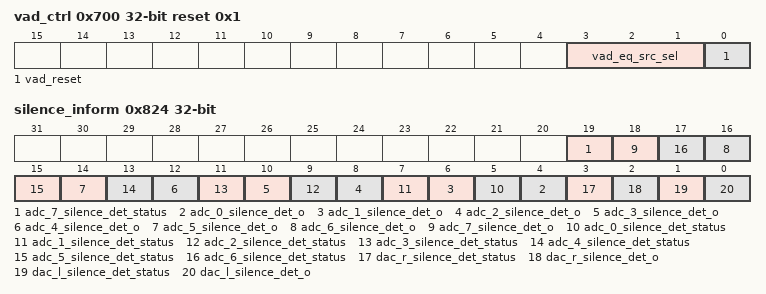
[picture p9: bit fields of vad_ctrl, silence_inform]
0x700 vad_ctrl reset 0x1 — VAD Control Register
  [3:1] vad_eq_src_sel — VAD source selection 2'b00: adc_0_eq_out 2'b01: adc_1_eq_out 2'b10: adc_2_eq_out 2'b11: adc_3_eq_out
  [0] vad_reset — Reset VAD module
0x704 vad_voice_level reset 0x2C
  [8:0] vad_voice_level — The minimum value of mean power of PE&D unit0
0x708 vad_det_thr reset 0x19 — VAD Detection Threshold Register
  [7:0] vad_det_thr — Setting vad_flag threshold between frame power and mean power of PE&D unit0
0x70C vad_intr_en — VAD Interrupt Enable Register
  [7:0] vad_intr_en — New enables of vad interrupts
0x800 ana_read ro
  [0] micbias_oc — The status flag of MICBIAS over-current protection
{0x804+4i} adc_{i}_lpf_rd ro (i=0..7) — ADC Channel {i} LPF RD Register
  [18:0] adc_{i}_lpf_rd — CH {i} ADC LPF out valus
0x824 silence_inform ro
  [19] adc_7_silence_det_status — Ongoing status of adc_7_silence detection 1'b0: adc_7_silencedetection is resting (clock is gating) 1'b1: adc_7_silencedetection is working
  [2n+4] adc_{n}_silence_det_o (n=0..7) — adc_{n}_silencedata status (result of silence detection) 1'b0: not adc_{n}_silencedata 1'b1: adc_{n}_silenceis detected
  [2n+5] adc_{n}_silence_det_status (n=0..6) — Ongoing status of adc_{n}_silencedetection 1'b0: adc_{n}_silencedetection is resting (clock is gating) 1'b1: adc_{n}_silencedetection is working
  [3] dac_r_silence_det_status — Ongoing status of dac_r_silence detection 1'b0: dac_r_silence detection is resting (clock is gating) 1'b1: dac_r_silence detection is working
  [2] dac_r_silence_det_o — dac_r_silence data status (result of silence detection) 1'b0: not dac_r_silence data 1'b1: dac_r_silence is detected
  [1] dac_l_silence_det_status — Ongoing status of dac_l_silence detection 1'b0: dac_l_silence detection is resting (clock is gating) 1'b1: dac_l_silence detection is working
  [0] dac_l_silence_det_o — dac_l_silence data status (result of silence detection) 1'b0: not dac_l_silence data 1'b1: dac_l_silence is detected
0x828 audio_ro_dummy1 ro
0x900 vad_intr_st ro — VAD Interrupt Status Register
  [7:0] vad_intr_st — Status of new VAD interrupts and clear them by writing 1
0x904 vad_det_flag ro — VAD Detection Flag Register
  [0] vad_det_flag — VAD detection flag
